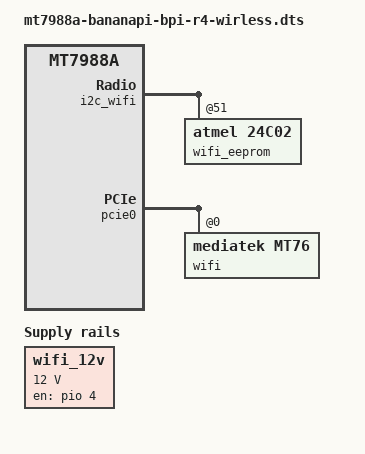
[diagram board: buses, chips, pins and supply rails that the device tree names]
// SPDX-License-Identifier: (GPL-2.0 OR MIT)
/dts-v1/;
/plugin/;

#include <dt-bindings/gpio/gpio.h>

/ {
	compatible = "bananapi,bpi-r4", "mediatek,mt7988a";

	fragment@0 {
		target-path = "/";
		__overlay__ {
			wifi_12v: regulator-wifi-12v {
				compatible = "regulator-fixed";
				regulator-name = "wifi";
				regulator-min-microvolt = <12000000>;
				regulator-max-microvolt = <12000000>;
				gpio = <&pio 4 GPIO_ACTIVE_HIGH>;
				enable-active-high;
				regulator-always-on;
			};
		};
	};

	fragment@1 {
		target = <&i2c_wifi>;
		__overlay__ {
			// It is disabled currently, but this doesn't actually seem to disable it.
			status = "okay";

			// There are not two eeproms on the production hardware.
			// I think two eeproms was a thing on the over 9000 antenna version.
			wifi_eeprom@51 {
				compatible = "atmel,24c02";
				reg = <0x51>;
				address-bits = <8>;
				page-size = <8>;
				size = <256>;

				// nvmem-layout is removed, as the EEPROM is blank by default.
			};
		};
	};

	fragment@2 {
		target = <&pcie0>;
		__overlay__ {
			pcie@0,0 {
				reg = <0x0000 0 0 0 0>;

				wifi@0,0 {
					compatible = "mediatek,mt76";
					reg = <0x0000 0 0 0 0>;
					// Contents are mt7996_eeprom_233.bin
					// We need the firmware here as it's the only way we can set the three macs reliably.
					// xxd -i mt7996_eeprom_233.bin, remove comma's, edit to 32bit hex values.
					mediatek,eeprom-data = <
						0x90790300 0x000c4326 0x6010000c
						0x43266011 0x00000000 0x00000000
						0x00000000 0x00000000 0x00000000
						0x00000000 0x00000000 0x00000000
						0x00000000 0x00000000 0x00000000
						0x00000000 0x00000000 0x00000000
						0x00000000 0x00000000 0x00000000
						0x00000000 0x00000000 0x00000000
						0x00000000 0x00000000 0x00000000
						0x00000000 0x00000000 0x00000000
						0x00000000 0x00000000 0x00000000
						0x00000000 0x00000000 0x00000000
						0x00000000 0x00000000 0x00000000
						0x00000000 0x00000000 0x00000000
						0x00000000 0x00000000 0x00000000
						0x00000000 0x00000000 0x00000000
						0x00000000 0x00000000 0x00000000
						0x00000000 0x00000000 0x00000000
						0x00000000 0x00000000 0x00000000
						0x00000000 0x00000000 0x00000000
						0x00000000 0x00000000 0x00000000
						0x00000000 0x00000000 0x00000000
						0x00000000 0x00000000 0x00000000
						0x00000000 0x00000000 0x00000000
						0x00000000 0x00000000 0x00000000
						0x00000000 0x00000000 0x00000000
						0x00000000 0x00000000 0x00000000
						0x00000000 0x00000000 0x00000000
						0x00000000 0x00000000 0x00000000
						0x00000000 0x00000000 0x00000000
						0x00000000 0x00000000 0x00000000
						0x00000000 0x00000000 0x00000000
						0x00000000 0x00000000 0x00000000
						0x00000000 0x11131b1a 0x131b0808
						0x600a0a0a 0x00008038 0x8000001a
						0x03000000 0x01010000 0x00100000
						0x00000000 0x00000000 0x00000000
						0x00000000 0x00000000 0x00000000
						0x00000000 0x00000000 0x00000000
						0x00000000 0x00000000 0x00000000
						0x00000000 0x00000000 0x00000000
						0x00000000 0x00000000 0x00000000
						0x00000000 0x00000000 0x00000000
						0x00000000 0x00000000 0x00000000
						0x00000000 0x00000000 0x00000000
						0x00000000 0x00000000 0x00000000
						0x00000000 0x00000000 0x00000000
						0x00000000 0x00000000 0x00000000
						0x00000000 0x00000000 0x00000000
						0x00000000 0x00000000 0x00000000
						0x00000000 0x00000000 0x00000000
						0x00000000 0x00000000 0x00000000
						0x00000000 0x00000000 0x00000000
						0x00000000 0x00000000 0x00000000
						0x00000000 0x00000000 0x00000000
						0x00000000 0x00000000 0x00000000
						0x00000000 0x00000000 0x00000000
						0x00000000 0x00000000 0x00000000
						0x00000000 0x00000000 0x000c4326
						0x60120000 0x00000000 0x00000000
						0x00000000 0x00000000 0x00000000
						0x00000000 0x00000000 0x00000000
						0x00000000 0x00000000 0x00000000
						0x00000000 0x00000000 0x00000000
						0x00000000 0x00000000 0x00000000
						0x00000000 0x00000000 0x00000000
						0x00000000 0x00000000 0x00000000
						0x00000000 0x00000000 0x00000000
						0x00000000 0x00000000 0x00000000
						0x00000000 0x00000000 0x00000000
						0x00000000 0x00000000 0x00000000
						0x00000000 0x00000000 0x00000000
						0x00000000 0x00000000 0x00000000
						0x00000000 0x00000000 0x00000000
						0x00000000 0x00000000 0x00000000
						0x00000000 0x00000000 0x00000000
						0x00000000 0x00000000 0x00000000
						0x00000000 0x00000000 0x00000000
						0x00000000 0x00000000 0x00000000
						0x00000000 0x00000000 0x00000000
						0x00000000 0x00000000 0x00000000
						0x00000000 0x00000000 0x00000000
						0x00000000 0x00000000 0x00000000
						0x00000000 0x00000000 0x00000000
						0x00000000 0x00000000 0x00000000
						0x00000000 0x00000000 0x00000000
						0x00000000 0x00000000 0x00000000
						0x00000000 0x00000000 0x00000000
						0x00000000 0x00000000 0x00000000
						0x00000000 0x00000000 0x00000000
						0x00000000 0x00000000 0x00000000
						0x00000000 0x00000000 0x00000000
						0x00000000 0x00000000 0x00000000
						0x00000000 0x00000000 0x00000000
						0x00000000 0x00000000 0x00000000
						0x00000000 0x00000000 0x00000000
						0x00000000 0x00000000 0x00000000
						0x00000000 0x00000000 0x00000000
						0x00000000 0x00000000 0x00000000
						0x00000000 0x00000000 0x00000000
						0x00000000 0x00000000 0x00000000
						0x00000000 0x00000000 0x00000000
						0x00000000 0x00000000 0x00000000
						0x00000000 0x00000000 0x00000000
						0x00000000 0x00000000 0x00000000
						0x00000000 0x00000000 0x00000000
						0x00000000 0x00000000 0x00000000
						0x00000000 0x00000000 0x00000000
						0x00000000 0x00000000 0x00000000
						0x00000000 0x00000000 0x00000000
						0x00000000 0x00000000 0x00000000
						0x00000000 0x00000000 0x00000000
						0x00000000 0x00000000 0x00000000
						0x00000000 0x00000000 0x00000000
						0x00000000 0x00000000 0x00000000
						0x00000000 0x00000000 0x00000000
						0x00000000 0x00000000 0x00000000
						0x00000000 0x00000000 0x00000000
						0x00000000 0x00000000 0x00000000
						0x00000000 0x00000000 0x00000000
						0x00000000 0x00000000 0x00000000
						0x00000000 0x00000000 0x00000000
						0x00000000 0x00000000 0x00000000
						0x00000000 0x00000000 0x00000000
						0x00000000 0x00000000 0x00000000
						0x00000000 0x00000000 0x00000000
						0x00000000 0x00000000 0x00000000
						0x00000000 0x00000000 0x00000000
						0x00000000 0x00000000 0x00000000
						0x00000000 0x22222222 0x66447766
						0x44776644 0x77664477 0x66447766
						0x44444466 0x44444466 0x44444466
						0x44444466 0x44444400 0x00000000
						0x00000000 0x00000000 0x00000000
						0x00000000 0x00000000 0x00000000
						0x00000000 0x00000000 0x00000000
						0x00000000 0x00000000 0x00000000
						0x00000000 0x00000000 0x00000000
						0x00000000 0x00000000 0x00000000
						0x00000000 0x00000000 0x00000000
						0x00000000 0x00000000 0x00000000
						0x00000000 0x00000000 0x00000000
						0x00000000 0x00000000 0x00000000
						0x00000000 0x00000000 0x00000000
						0x00000000 0x00000000 0x00000000
						0x00000000 0x00000000 0x00000000
						0x00000000 0x00000000 0x00000000
						0x00000000 0x00000000 0x00000000
						0x00000000 0x00000000 0x00000000
						0x00800080 0x00800a0a 0x00404040
						0x00000000 0x00000000 0x00000000
						0x00000000 0x00000000 0x00000000
						0x00000000 0x00000000 0x00000000
						0x00000000 0x00000000 0x00000000
						0x00000000 0x00000000 0x00000000
						0x00000000 0x00000000 0x00000000
						0x00000000 0x00000000 0x00000000
						0x00000000 0x00000000 0x00000000
						0x00000000 0x00000000 0x00000000
						0x00000000 0x00000000 0x00000000
						0x00000000 0x00000000 0x00000000
						0x00000000 0x00000000 0x00000000
						0x00000000 0x00000000 0x00000000
						0x00000000 0x00000000 0x00000000
						0x00000000 0x00000000 0x00000000
						0x00000000 0x00000000 0x00000000
						0x00000000 0x00000000 0x00000000
						0x00000000 0x00000000 0x00000000
						0x00000000 0x00000000 0x00000000
						0x00000000 0x00000000 0x00000000
						0x00000000 0x00000000 0x00000002
						0x20000000 0x00000220 0x00000000
						0x00022000 0x00000000 0x02200000
						0x00000002 0x20000000 0x00000220
						0x00000000 0x00022000 0x00000000
						0x02200000 0x00000002 0x20000000
						0x00000220 0x00000000 0x00022000
						0x00000000 0x02200000 0x00000002
						0x20000000 0x00000220 0x00000000
						0x00022000 0x00000000 0x02200000
						0x00000002 0x27000000 0x00000227
						0x00000000 0x00022700 0x00000000
						0x02270000 0x00000002 0x27000000
						0x00000227 0x00000000 0x00022700
						0x00000000 0x02270000 0x00000002
						0x27000000 0x00000227 0x00000000
						0x00022700 0x00000000 0x02270000
						0x00000002 0x27000000 0x00000227
						0x00000000 0x00022700 0x00000000
						0x02270000 0x00000002 0x00000000
						0x00000200 0x00000000 0x00020000
						0x00000000 0x02000000 0x00000002
						0x27000000 0x00000227 0x00000000
						0x00022700 0x00000000 0x02270000
						0x00000002 0x27000000 0x00000227
						0x00000000 0x00022700 0x00000000
						0x02270000 0x00000002 0x27000000
						0x00000227 0x00000000 0x00022700
						0x00000000 0x02270000 0x00000002
						0x27000000 0x00000227 0x00000000
						0x02270000 0x00000000 0x02270000
						0x00000000 0x00000000 0x00000000
						0x00000000 0x00000000 0x00000000
						0x00000000 0x00000000 0x00000000
						0x00000000 0x00000000 0x00000000
						0x00000000 0x00000000 0x00000000
						0x00000000 0x00000000 0x00000000
						0x00000000 0x00000000 0x00000000
						0x00000000 0x00000000 0x00000000
						0x00000000 0x00000000 0x00000000
						0x00000000 0x00000000 0x00000000
						0x00000000 0x00000000 0x00000000
						0x00000000 0x00000000 0x00000000
						0x00000000 0x00000000 0x00000000
						0x00000000 0x00000000 0x00000000
						0x00000000 0x00000000 0x00000000
						0x00000000 0x00000000 0x00000000
						0x00000000 0x02020280 0x7f000000
						0x00000000 0x00000000 0x00000000
						0x00000000 0x00000000 0x00000000
						0x00000000 0x00000000 0x00000000
						0x00000000 0x00000000 0x00000000
						0x00000000 0x00000000 0x00000000
						0x00000000 0x20252b31 0x363b4146
						0x00564c52 0x575d6167 0x6d10161c
						0x22282e35 0x3c005042 0x484e545a
						0x60660000 0x00000000 0x00000000
						0x00000000 0x00000000 0x00000000
						0x00000000 0x00000000 0x00000000
						0x00000000 0x00000000 0x00000000
						0x00000000 0x00000000 0x00000000
						0x00000000 0x00000000 0x00000000
						0x00000000 0x00000000 0x00000000
						0x00000000 0x00000000 0x00000000
						0x00000000 0x00000000 0x00000000
						0x00000000 0x00000000 0x00000000
						0x00000000 0x00000000 0x00000000
						0x00000000 0x00000000 0x00000000
						0x00000000 0x00000000 0x00000000
						0x00000000 0x00000000 0x00000000
						0x00000000 0x00000000 0x00000000
						0x00000000 0x00000000 0x00000000
						0x00000000 0x00000000 0x00000000
						0x00000000 0x00000000 0x00000000
						0x00000000 0x00000000 0x00000000
						0x00000000 0x00000000 0x00000000
						0x00000000 0x00000000 0x00000000
						0x00000000 0x00000000 0x00000000
						0x00000000 0x00000000 0x00000000
						0x00000000 0x00000000 0x00000000
						0x00000000 0x00000000 0x00000000
						0x00000000 0x00000000 0x00000000
						0x00000000 0x00000000 0x00000000
						0x00000000 0x00000000 0x00000000
						0x00000000 0x00000000 0x00000000
						0x00000000 0x00000000 0x00000000
						0x00000000 0x00000000 0x00000000
						0x00000000 0x00000000 0x00000000
						0x00000000 0x00000000 0x00000000
						0x00000000 0x00000000 0x00000000
						0x00000000 0x00000000 0x00000000
						0x00000000 0x00000000 0x00000000
						0x00000000 0x00000000 0x00000000
						0x00000000 0x00000000 0x00000000
						0x00000000 0x00000000 0x00000000
						0x00000000 0x00000000 0x00000000
						0x00000000 0x00000000 0x00000000
						0x00000000 0x00000000 0x00000000
						0x00000000 0x00000000 0x00000000
						0x00000000 0x00000000 0x00000000
						0x00000000 0x00000000 0x00000000
						0x00000000 0x00000000 0x00000000
						0x00000000 0x00000000 0x00000000
						0x00000000 0x00000000 0x00000000
						0x00000000 0x00000000 0x00000000
						0x00000000 0x00000000 0x00000000
						0x00000000 0x00000000 0x00000000
						0x00000000 0x00000000 0x00000000
						0x00000000 0x00000000 0x00000000
						0x00000000 0x00000000 0x00000000
						0x00000000 0x00000000 0x00000000
						0x00000000 0x00000000 0x00000000
						0x00000000 0x00000000 0x00000000
						0x00000000 0x00000000 0x00000000
						0x00000000 0x00000000 0x00000000
						0x00000000 0x00000000 0x00000000
						0x00000000 0x00000000 0x00000000
						0x00000000 0x00000000 0x00000000
						0x00000000 0x00000000 0x00000000
						0x00000000 0x00000000 0x00000000
						0x00000000 0x00000000 0x00000000
						0x00000000 0x00000000 0x00000000
						0x00000000 0x000040bd 0x40bd40bd
						0x40bd40bd 0x40bd40bd 0x40bd40c8
						0x40c640c6 0x40c740c7 0x40c840c7
						0x40c640c7 0x40c740c7 0x40c640c5
						0x40c640c6 0x40c540c4 0x40c440c4
						0x40c30000 0x00000000 0x00000000
						0x00000000 0x00000000 0x00000000
						0x00000000 0x00000000 0x00000000
						0x00000000 0x00000000 0x00000000
						0x00000000 0x00000000 0x00000000
						0x00000000 0x00000000 0x00000000
						0x00000000 0x00000000 0x00000000
						0x00000000 0x00000000 0x00000000
						0x00000000 0x00000000 0x00000000
						0x00000000 0x00000000 0x00000000
						0x00000000 0x00000000 0x00000000
						0x00000000 0x00000000 0x00000000
						0x00000000 0x00000000 0x00000000
						0x00000000 0x00000000 0x02000000
						0x00000000 0x00000000 0x00000000
						0x00000000 0x00000000 0x00000000
						0x00000000 0x00000000 0x00000000
						0x00000000 0x00000000 0x00000000
						0x00000000 0x00000000 0x00000000
						0x00000000 0x00000000 0x00000000
						0x00000000 0x00000000 0x00000000
						0x00000000 0x00000000 0x00000000
						0x00000000 0x00000000 0x00000000
						0x000000d1 0xd1d1dddd 0xdde9e9e9
						0xf5f5f501 0x01010909 0x09151515
						0xd1d1d1dd 0xdddde9e9 0xe9f5f5f5
						0xfdfdfd09 0x09091515 0x15d1d1d1
						0xdddddde9 0xe9e9f5f5 0xf5ffffff
						0x07070719 0x1919d7d7 0xd7e3e3e3
						0xefefeff7 0xf7f70303 0x03171717
						0x1f1f1fcf 0xcfcfdbdb 0xdbe7e7e7
						0xf3f3f3ff 0xffff1313 0x13171717
						0xd7d7d7e3 0xe3e3efef 0xeff7f7f7
						0x03030311 0x11111919 0x19cfcfcf
						0xdbdbdbe7 0xe7e7f3f3 0xf3ffffff
						0x13131317 0x1717d7d7 0xd7e3e3e3
						0xefefeff7 0xf7f70303 0x03111111
						0x191919cf 0xcfcfdbdb 0xdbe7e7e7
						0xf3f3f3ff 0xffff1313 0x13171717
						0x00000000 0x00000000 0x00000000
						0x00000000 0x00000000 0x00000000
						0x00000000 0x00000000 0x00000000
						0x00000000 0x00000000 0x00000000
						0x00000000 0x00000000 0x00000000
						0x00000000 0x00000000 0x00000000
						0x00000000 0x00000000 0x00000000
						0x00000000 0x00000000 0x00000000
						0x00000000 0x00000000 0x00000000
						0x00000000 0x00000000 0x00000000
						0x00000000 0x00000000 0x00000000
						0x00000000 0x00000000 0x00000000
						0x00000000 0x00000000 0x00000000
						0x00000000 0x00000000 0x00000000
						0x00000000 0x00000000 0x00000000
						0x00000000 0x00000000 0x00000000
						0x00000000 0x00000000 0x00000000
						0x00000000 0x00000000 0x00000000
						0x00000000 0x00000000 0x00000000
						0x00000000 0x00000000 0x00000000
						0x00000000 0x00000000 0x00000000
						0x00000000 0x00000000 0x00000000
						0x00000000 0x00000000 0x00000000
						0x00000000 0x00000000 0x00000000
						0x00000000 0x00000000 0x00000000
						0x00000000 0x00000000 0x00000000
						0x00000000 0x00000000 0x00000000
						0x00000000 0x00000000 0x00000000
						0x00000000 0x00000000 0x00000000
						0x00000000 0x00000000 0x00000000
						0x00000000 0x00000000 0x00000000
						0x00000000 0x00000000 0x00000000
						0x00000000 0x00000000 0x00000000
						0x00000000 0x00000000 0x00000000
						0x00000000 0x00000000 0x00000000
						0x00000000 0x00000000 0x00000000
						0x00000000 0x00000000 0x00000000
						0x00000000 0x00000000 0x00000000
						0x00000000 0x00000000 0x00000000
						0x00000000 0x00000000 0x00000000
						0x00000000 0x00000000 0x00000000
						0x00000000 0x00000000 0x00000000
						0x00000000 0x00000000 0x00000000
						0x00000000 0x00000000 0x00000000
						0x00000000 0x00000000 0x00000000
						0x00000000 0x00000000 0x00000000
						0x00000000 0x00000000 0x00000000
						0x00000000 0x00000000 0x00000000
						0x00000000 0x00000000 0x00000000
						0x00000000 0x00000000 0x00000000
						0x00000000 0x00000000 0x00000000
						0x00000000 0x00000000 0x00000000
						0x00000000 0x00000000 0x00000000
						0x00000000 0x00000000 0x00000000
						0x00000000 0x00000000 0x00000000
						0x00000000 0x00000000 0x00000000
						0x00000000 0x00000000 0x00d7d700
						0x00000000 0x00000000 0x00000000
						0x00000000 0x00000000 0x00000000
						0x00000000 0x00000000 0x00000000
						0x00000000 0x00000000 0x00000000
						0x00000000 0x00000000 0x00000000
						0x00000000 0x00000000 0x00000000
						0x00000000 0x00000000 0x00000000
						0x00000000 0x00000000 0x00000000
						0x00000000 0x00000000 0x00000000
						0x00000000 0x00000000 0x00000000
						0x00000000 0x00000000 0x00000000
						0x00000000 0x00000000 0x00000000
						0x00000000 0x29272727 0x27250000
						0x00000000 0x00000000 0x22242424
						0x21212121 0x00000000 0x00000000
						0x00000000 0x00000000 0x00000080
						0x80c18080 0x80808080 0x80808080
						0x80808080 0x808080c1 0x80c180c1
						0xc18080c1 0x80808080 0x80808080
						0x80808000 0x00000000 0x00000000
						0x00000000 0x00000000 0x00000000
						0x00000000 0x00000000 0x00000000
						0x00808080 0x80808080 0x80808080
						0x80808080 0x80808080 0x80808080
						0x80808080 0x80808080 0x80808080
						0x80808080 0x80808080 0x80808080
						0x80808080 0x80808080 0x80808080
						0x80000000 0x00000000 0x00000000
						0x00000000 0x00000000 0x00000000
						0x00000000 0x00000000 0x00000000
						0x00000000 0x00000000 0x00000000
						0x00000000 0x00000000 0x00000000
						0x00000000 0x00000000 0x00000000
						0x00000000 0x00000000 0xc6c6c4c4
						0xc30000c1 0xc1c18383 0x83838386
						0x86c1c183 0x83838383 0x8686c1c1
						0xc1818181 0x82838585 0x86868888
						0xc1c1c181 0x81818283 0x85858686
						0x8888c1c1 0xc1818181 0x82838585
						0x86868888 0xc1c1c181 0x81818283
						0x85858686 0x8888c1c1 0xc1818181
						0x82838585 0x86868888 0xc1c1c181
						0x81818283 0x85858686 0x8888c1c1
						0xc1818181 0x82838585 0x86868888
						0xc1c5c5c3 0xc100c2c2 0xc2c2c2c1
						0x00818383 0xc1c1c1c1 0x00008183
						0x83c2c1c1 0xc1c10000 0x818383c1
						0xc2c2c2c2 0xc1008183 0x83848487
						0x87c2c1c1 0xc1c10000 0x81838384
						0x848888c1 0xc1c1c1c1 0x00008183
						0x83868689 0x89c1c181 0x81838484
						0x84858686 0x88888b8b 0x8281c2c2
						0xc2c2c100 0x81838384 0x848787c2
						0xc2c2c2c2 0xc1008183 0x83848487
						0x87c2c2c2 0xc2c2c100 0x81838384
						0x848787c2 0xc2c2c2c2 0xc1008183
						0x83848487 0x87c2c2c2 0xc2c2c100
						0x81838384 0x848787c2 0xc1c1c1c1
						0x00008183 0x83868689 0x89c18181
						0x83848484 0x85868688 0x888b8b81
						0x81818384 0x84848586 0x8688888b
						0x8b81c5c5 0xc3c100c2 0xc2c2c200
						0x81828383 0x85858787 0xc2c2c2c2
						0xc2008182 0x83838585 0x8787c2c1
						0xc1c1c181 0x82838484 0x86868a8a
						0xc1c18282 0x84848484 0x84858586
						0x868c8c82 0x82c2c2c2 0xc2008182
						0x83838585 0x8787c2c2 0xc2c2c200
						0x81828383 0x85858787 0xc2c2c2c2
						0xc2008182 0x83838585 0x8787c2c2
						0xc2c2c200 0x81828383 0x85858787
						0xc2c2c2c2 0xc2008182 0x83838585
						0x8787c2c1 0xc1c1c181 0x82838484
						0x86868a8a 0xc1c18282 0x00000000
						0x00000000 0x00000000 0x00000000
						0x00000000 0x00000000 0x00000000
						0x00000000 0x84848484 0x84858586
						0x868c8c82 0x82828284 0x84848484
						0x85858686 0x8c8c8282 0x87878888
						0x88888888 0x8888888d 0x8d878787
						0x87888888 0x88888888 0x88888d8d
						0x87878787 0x88888888 0x88888888
						0x888d8d87 0x87878788 0x88888888
						0x88888888 0x8d8d8787 0x00818181
						0x00000000 0x00000000 0x00000000
						0x00000000 0x00000000 0x82830000
						0x00000000 0xc4c1c4c1 0x80c280c1
						0xc180c1c2 0xc3c1c4c1 0xc1c280c3
						0xc1c1c1c3 0xc4c4c5c1 0xc2c480c4
						0xc3c2c2c2 0x80808080 0x80808080
						0x80808080 0x00000000 0x00000000
						0x00000000 0x80808080 0x80808080
						0x80808080 0x80808080 0x80808080
						0x80808080 0x80808080 0x80808080
						0x80808080 0x80808080 0x80808080
						0x80808080 0x00000000 0x00000000
						0x00000000 0x85868685 0x80828481
						0x87868584 0x82c1c286 0x87828387
						0x85828d8d 0x8d909090 0x85838486
						0x82808180 0x868480c1 0x80c1c284
						0x86818086 0x81808d8d 0x8d909090
						0x83848386 0x81c18080 0x87858280
						0xc1c2c483 0x86808086 0x82808d8d
						0x8d909090 0x8c8c8c8c 0x8c8c8c8c
						0x8f8f8f8f 0x8f8f8d8e 0x8e8e8e91
						0x91918d8d 0x8d909090 0x00000000
						0x00000000 0x00000000 0x00000000
						0x00000000 0x00000000 0x00000000
						0x80808080 0x80808080 0x80808080
						0x80808080 0x80808080 0x80808080
						0x80808080 0x80808080 0x80808080
						0x80808080 0x80808080 0x80808080
						0x80808080 0x80808080 0x80808080
						0x80808080 0x80808080 0x80808080
						0x80808080 0x80808080 0x80808080
						0x80808080 0x80808080 0x80808080
						0x80808080 0x00000000 0x00000000
						0x00000000 0x00000000 0x00000000
						0x00000000 0x00000000 0x00000000
						0x80808080 0x80808080 0x80808080
						0x00000000 0x00000000 0x00000000
						0x00000000 0x00000000 0x00000000
						0x00000000 0x00000000 0x00000000
						0x00000000 0x00000000 0x00000000
						0x00000000 0x00000000 0x00000000
						0x00000000 0x00000000 0x00000000
						0x00000000 0x00000000 0x00000000
						0x00000000 0x00000000 0x00000000
						0x00000000 0x00000000 0x00000000
						0x00000000 0x00000000 0x00000000
						0x00000000 0x00000000 0x00000000
						0x00000000 0x00000000 0x00000000
						0x00000000 0x00000000 0x00000000
						0x00000000 0x00000000 0x00000000
						0x00000000 0x00000000 0x00000000
						0x00000000 0x00000000 0x00000000
						0x00000000 0x00000000 0x00000000
						0x00000000 0x00000000 0x00000000
						0x00000000 0x00000000 0x00000000
						0x00000000 0x00000000 0x00000000
						0x00000000 0x00000000 0x00000000
						0x00000000 0x00000000 0x00000000
						0x00000000 0x00000000 0x00000000
						0x00000000 0x00000000 0x00000000
						0x00000000 0x00000000 0x00000000
						0x00000000 0x00000000 0x00000000
						0x00000000 0x00000000 0x00000000
						0x00000000 0x00000000 0x00000000
						0x00000000 0x00000000 0x00000000
						0x00000000 0x00000000 0x00000000
						0x00000000 0x00000000 0x00000000
						0x00000000 0x00000000 0x00000000
						0x00000000 0x00000000 0x00000000
						0x00000000 0x00000000 0x00000000
						0x00000000 0x00000000 0x00000000
						0x00000000 0x00000000 0x00000000
						0x00000000 0x00000000 0x00000000
						0x00000000 0x00000000 0x00000000
						0x00000000 0x00000000 0x00000000
						0x00000000 0x00000000 0x00000000
						0x00000000 0x00000000 0x00000000
						0x00000000 0x00000000 0x00000000
						0x00000000 0x00000000 0x00000000
						0x00000000 0x00000000 0x00000000
						0x00000000 0x00000000 0x00000000
						0x00000000 0x00000000 0x00000000
						0x00000000 0x00000000 0x00000000
						0x00000000 0x00000000 0x00000000
						0x00000000 0x00000000 0x00000000
						0x00000000 0x00000000 0x00000000
						0x00000000 0x00000000 0x00000000
						0x00000000 0x00000000 0x00000000
						0x00000000 0x00000000 0x00000000
						0x00000000 0x00000000 0x00000000
						0x00000000 0x00000000 0x00000000
						0x00000000 0x00000000 0x00000000
						0x00000000 0x00000000 0x00000000
						0x00000000 0x00000000 0x00000000
						0x00000000 0x00000000 0x00000000
						0x00000000 0x00000000 0x00000000
						0x00000000 0x00000000 0x00000000
						0x00000000 0x00000000 0x00000000
						0x00000000 0x00000000 0x00000000
						0x00000000 0x00000000 0x00000000
						0x00000000 0x00000000 0x00000000
						0x00000000 0x00000000 0x00000000
						0x00000000 0x00000000 0x00000000
						0x00000000 0x00000000 0x00000000
						0x00000000 0x00000000 0x00000000
						0x00000000 0x00000000 0x00000000
						0x00000000 0x00000000 0x00000000
						0x00000000 0x00000000 0x00000000
						0x00000000 0x00000000 0x00000000
						0x00000000 0x00000000 0x00000000
						0x00000000 0x00000000 0x00000000
						0x00000a00 0x000c0000 0x0d000000
						0x00000000 0x00000000 0x00000000
						0x00000000 0x00000000 0x00000000
						0x00000000 0x00000000 0x00000000
						0x2f7f7f7f 0x13110f2c 0x007f7f00
						0x110a0000 0x2f7f7f7f 0x13110f2c
						0x007f7f00 0x110a0000 0x00000000
						0x00000000 0x00000000 0x00000000
						0x00000000 0x00000000 0x00000000
						0x00000000 0x00000000 0x00000000
						0x00000000 0x00000000 0x00000000
						0x00000000 0x00000000 0x00000000
						0x00000000 0x00000000 0x00000000
						0x00000000 0x00000000 0x00000000
						0x00000000 0x00000000 0x00000000
						0x00000000 0x00000000 0x00000000
						0x00000000 0x00000000 0x00000000
						0x00000000 0x00000000 0x00000000
						0x00000000 0x00000000 0x00000000
						0x00000000 0x00000000 0x00000000
						0x00000000 0x00000000 0x00000000
						0x00000000 0x00000000 0x00000000
						0x00000000 0x00000000 0x00000000
						0x00000000 0x00000000 0x00000000
						0x00000000 0x00000000 0x00000000
						0x00000000 0x00000000 0x00000000
						0x00000000 0x00000000 0x00000000
						0x00000000 0x00000000 0x00000000
						0x00000000 0x00000000 0x00000000
						0x00000000 0x00000000 0x00000000
						0x00000000 0x00000000 0x00000000
						0x00000000 0x00000000 0x00000000
						0x00000000 0x00000000 0x00000000
						0x00000000 0x00000000 0x00000000
						0x00000000 0x00000000 0x00000000
						0x00000000 0x00000000 0x00000000
						0x00000000 0x00000000 0x00000000
						0x00000000 0x00000000 0x00000000
						0x00000000 0x00000000 0x00000000
						0x00000000 0x00000000 0x00000000
						0x00000000 0x00000000 0x00000000
						0x00000000 0x00000000 0x00000000
						0x00000000 0x00000000 0x00000000
						0x00000000 0x00000000 0x00000000
						0x00000000 0x00000000 0x00000000
						0x00000000 0x00000000 0x00000000
						0x00000000 0x00000000 0x00000000
						0x00000000 0x00000000 0x00000000
						0x00000000 0x00000000 0x00000000
						0x00000000 0x00000000 0x00000000
						0x00000000 0x00000000 0x00000000
						0x00000000 0x00000000 0x00000000
					>;
				};
			};
		};
	};
};
